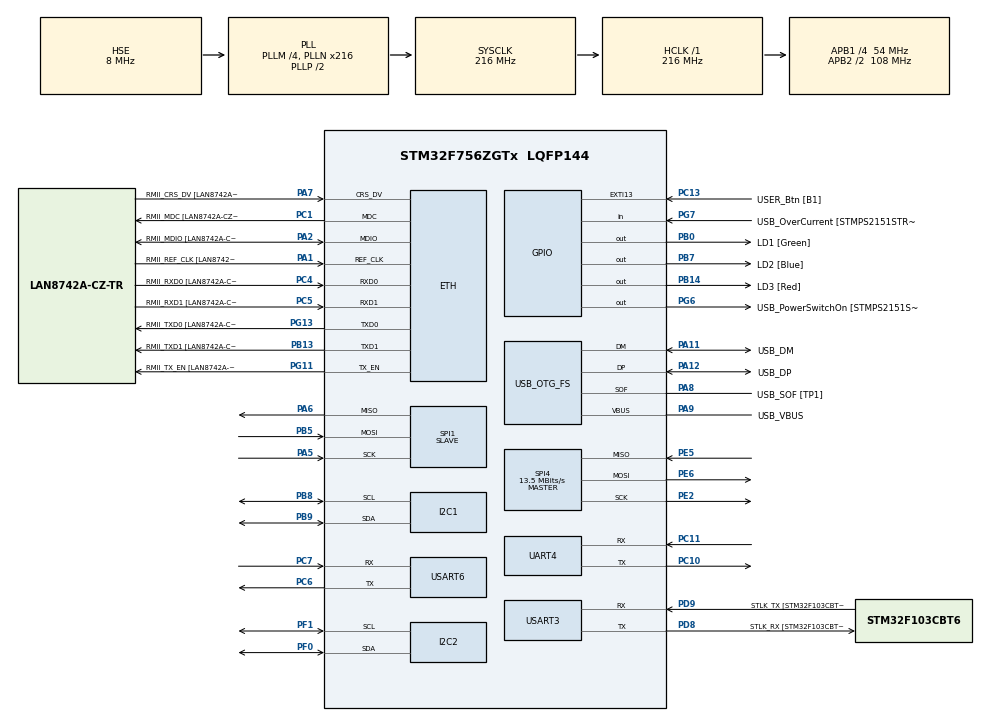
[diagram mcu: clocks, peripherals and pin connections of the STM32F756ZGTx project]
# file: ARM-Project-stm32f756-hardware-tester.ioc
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ADC1.Channel-0\#ChannelRegularConversion=ADC_CHANNEL_VREFINT
ADC1.NbrOfConversionFlag=1
ADC1.Rank-0\#ChannelRegularConversion=1
ADC1.SamplingTime-0\#ChannelRegularConversion=ADC_SAMPLETIME_480CYCLES
ADC1.master=1
CORTEX_M7.default_mode_Activation=1
Dma.ADC1.4.Direction=DMA_PERIPH_TO_MEMORY
Dma.ADC1.4.FIFOMode=DMA_FIFOMODE_DISABLE
Dma.ADC1.4.Instance=DMA2_Stream4
Dma.ADC1.4.MemDataAlignment=DMA_MDATAALIGN_HALFWORD
Dma.ADC1.4.MemInc=DMA_MINC_ENABLE
Dma.ADC1.4.Mode=DMA_NORMAL
Dma.ADC1.4.PeriphDataAlignment=DMA_PDATAALIGN_HALFWORD
Dma.ADC1.4.PeriphInc=DMA_PINC_DISABLE
Dma.ADC1.4.Priority=DMA_PRIORITY_LOW
Dma.I2C1_RX.7.Direction=DMA_PERIPH_TO_MEMORY
Dma.I2C1_RX.7.FIFOMode=DMA_FIFOMODE_DISABLE
Dma.I2C1_RX.7.Instance=DMA1_Stream0
Dma.I2C1_RX.7.MemDataAlignment=DMA_MDATAALIGN_BYTE
Dma.I2C1_RX.7.MemInc=DMA_MINC_ENABLE
Dma.I2C1_RX.7.Mode=DMA_NORMAL
Dma.I2C1_RX.7.PeriphDataAlignment=DMA_PDATAALIGN_BYTE
Dma.I2C1_RX.7.PeriphInc=DMA_PINC_DISABLE
Dma.I2C1_RX.7.Priority=DMA_PRIORITY_LOW
Dma.I2C1_TX.8.Direction=DMA_MEMORY_TO_PERIPH
Dma.I2C1_TX.8.FIFOMode=DMA_FIFOMODE_DISABLE
Dma.I2C1_TX.8.Instance=DMA1_Stream6
Dma.I2C1_TX.8.MemDataAlignment=DMA_MDATAALIGN_BYTE
Dma.I2C1_TX.8.MemInc=DMA_MINC_ENABLE
Dma.I2C1_TX.8.Mode=DMA_NORMAL
Dma.I2C1_TX.8.PeriphDataAlignment=DMA_PDATAALIGN_BYTE
Dma.I2C1_TX.8.PeriphInc=DMA_PINC_DISABLE
Dma.I2C1_TX.8.Priority=DMA_PRIORITY_LOW
Dma.I2C2_RX.5.Direction=DMA_PERIPH_TO_MEMORY
Dma.I2C2_RX.5.FIFOMode=DMA_FIFOMODE_DISABLE
Dma.I2C2_RX.5.Instance=DMA1_Stream3
Dma.I2C2_RX.5.MemDataAlignment=DMA_MDATAALIGN_BYTE
Dma.I2C2_RX.5.MemInc=DMA_MINC_ENABLE
Dma.I2C2_RX.5.Mode=DMA_NORMAL
Dma.I2C2_RX.5.PeriphDataAlignment=DMA_PDATAALIGN_BYTE
Dma.I2C2_RX.5.PeriphInc=DMA_PINC_DISABLE
Dma.I2C2_RX.5.Priority=DMA_PRIORITY_LOW
Dma.I2C2_TX.6.Direction=DMA_MEMORY_TO_PERIPH
Dma.I2C2_TX.6.FIFOMode=DMA_FIFOMODE_DISABLE
Dma.I2C2_TX.6.Instance=DMA1_Stream7
Dma.I2C2_TX.6.MemDataAlignment=DMA_MDATAALIGN_BYTE
Dma.I2C2_TX.6.MemInc=DMA_MINC_ENABLE
Dma.I2C2_TX.6.Mode=DMA_NORMAL
Dma.I2C2_TX.6.PeriphDataAlignment=DMA_PDATAALIGN_BYTE
Dma.I2C2_TX.6.PeriphInc=DMA_PINC_DISABLE
Dma.I2C2_TX.6.Priority=DMA_PRIORITY_LOW
Dma.Request0=SPI1_RX
Dma.Request1=SPI1_TX
Dma.Request10=UART4_TX
Dma.Request11=USART6_RX
Dma.Request12=USART6_TX
Dma.Request2=SPI4_RX
Dma.Request3=SPI4_TX
Dma.Request4=ADC1
Dma.Request5=I2C2_RX
Dma.Request6=I2C2_TX
Dma.Request7=I2C1_RX
Dma.Request8=I2C1_TX
Dma.Request9=UART4_RX
Dma.SPI1_RX.0.Direction=DMA_PERIPH_TO_MEMORY
Dma.SPI1_RX.0.FIFOMode=DMA_FIFOMODE_DISABLE
Dma.SPI1_RX.0.Instance=DMA2_Stream0
Dma.SPI1_RX.0.MemDataAlignment=DMA_MDATAALIGN_BYTE
Dma.SPI1_RX.0.MemInc=DMA_MINC_ENABLE
Dma.SPI1_RX.0.Mode=DMA_NORMAL
Dma.SPI1_RX.0.PeriphDataAlignment=DMA_PDATAALIGN_BYTE
Dma.SPI1_RX.0.PeriphInc=DMA_PINC_DISABLE
Dma.SPI1_RX.0.Priority=DMA_PRIORITY_LOW
Dma.SPI1_TX.1.Direction=DMA_MEMORY_TO_PERIPH
Dma.SPI1_TX.1.FIFOMode=DMA_FIFOMODE_DISABLE
Dma.SPI1_TX.1.Instance=DMA2_Stream5
Dma.SPI1_TX.1.MemDataAlignment=DMA_MDATAALIGN_BYTE
Dma.SPI1_TX.1.MemInc=DMA_MINC_ENABLE
Dma.SPI1_TX.1.Mode=DMA_NORMAL
Dma.SPI1_TX.1.PeriphDataAlignment=DMA_PDATAALIGN_BYTE
Dma.SPI1_TX.1.PeriphInc=DMA_PINC_DISABLE
Dma.SPI1_TX.1.Priority=DMA_PRIORITY_LOW
Dma.SPI4_RX.2.Direction=DMA_PERIPH_TO_MEMORY
Dma.SPI4_RX.2.FIFOMode=DMA_FIFOMODE_DISABLE
Dma.SPI4_RX.2.Instance=DMA2_Stream3
Dma.SPI4_RX.2.MemDataAlignment=DMA_MDATAALIGN_BYTE
Dma.SPI4_RX.2.MemInc=DMA_MINC_ENABLE
Dma.SPI4_RX.2.Mode=DMA_NORMAL
Dma.SPI4_RX.2.PeriphDataAlignment=DMA_PDATAALIGN_BYTE
Dma.SPI4_RX.2.PeriphInc=DMA_PINC_DISABLE
Dma.SPI4_RX.2.Priority=DMA_PRIORITY_LOW
Dma.SPI4_TX.3.Direction=DMA_MEMORY_TO_PERIPH
Dma.SPI4_TX.3.FIFOMode=DMA_FIFOMODE_DISABLE
Dma.SPI4_TX.3.Instance=DMA2_Stream1
Dma.SPI4_TX.3.MemDataAlignment=DMA_MDATAALIGN_BYTE
Dma.SPI4_TX.3.MemInc=DMA_MINC_ENABLE
Dma.SPI4_TX.3.Mode=DMA_NORMAL
Dma.SPI4_TX.3.PeriphDataAlignment=DMA_PDATAALIGN_BYTE
Dma.SPI4_TX.3.PeriphInc=DMA_PINC_DISABLE
Dma.SPI4_TX.3.Priority=DMA_PRIORITY_LOW
Dma.UART4_RX.9.Direction=DMA_PERIPH_TO_MEMORY
Dma.UART4_RX.9.FIFOMode=DMA_FIFOMODE_DISABLE
Dma.UART4_RX.9.Instance=DMA1_Stream2
Dma.UART4_RX.9.MemDataAlignment=DMA_MDATAALIGN_BYTE
Dma.UART4_RX.9.MemInc=DMA_MINC_ENABLE
Dma.UART4_RX.9.Mode=DMA_NORMAL
Dma.UART4_RX.9.PeriphDataAlignment=DMA_PDATAALIGN_BYTE
Dma.UART4_RX.9.PeriphInc=DMA_PINC_DISABLE
Dma.UART4_RX.9.Priority=DMA_PRIORITY_LOW
Dma.UART4_TX.10.Direction=DMA_MEMORY_TO_PERIPH
Dma.UART4_TX.10.FIFOMode=DMA_FIFOMODE_DISABLE
Dma.UART4_TX.10.Instance=DMA1_Stream4
Dma.UART4_TX.10.MemDataAlignment=DMA_MDATAALIGN_BYTE
Dma.UART4_TX.10.MemInc=DMA_MINC_ENABLE
Dma.UART4_TX.10.Mode=DMA_NORMAL
Dma.UART4_TX.10.PeriphDataAlignment=DMA_PDATAALIGN_BYTE
Dma.UART4_TX.10.PeriphInc=DMA_PINC_DISABLE
Dma.UART4_TX.10.Priority=DMA_PRIORITY_LOW
Dma.USART6_RX.11.Direction=DMA_PERIPH_TO_MEMORY
Dma.USART6_RX.11.FIFOMode=DMA_FIFOMODE_DISABLE
Dma.USART6_RX.11.Instance=DMA2_Stream2
Dma.USART6_RX.11.MemDataAlignment=DMA_MDATAALIGN_BYTE
Dma.USART6_RX.11.MemInc=DMA_MINC_ENABLE
Dma.USART6_RX.11.Mode=DMA_NORMAL
Dma.USART6_RX.11.PeriphDataAlignment=DMA_PDATAALIGN_BYTE
Dma.USART6_RX.11.PeriphInc=DMA_PINC_DISABLE
Dma.USART6_RX.11.Priority=DMA_PRIORITY_LOW
Dma.USART6_TX.12.Direction=DMA_MEMORY_TO_PERIPH
Dma.USART6_TX.12.FIFOMode=DMA_FIFOMODE_DISABLE
Dma.USART6_TX.12.Instance=DMA2_Stream6
Dma.USART6_TX.12.MemDataAlignment=DMA_MDATAALIGN_BYTE
Dma.USART6_TX.12.MemInc=DMA_MINC_ENABLE
Dma.USART6_TX.12.Mode=DMA_NORMAL
Dma.USART6_TX.12.PeriphDataAlignment=DMA_PDATAALIGN_BYTE
Dma.USART6_TX.12.PeriphInc=DMA_PINC_DISABLE
Dma.USART6_TX.12.Priority=DMA_PRIORITY_LOW
ETH.MediaInterface=HAL_ETH_RMII_MODE
ETH.PHY_Name=LAN8742A_PHY_ADDRESS
ETH.PHY_Value=0
ETH.PhyAddress=0
I2C1.OwnAddress=0x10
I2C1.Timing=0x20404768
I2C2.OwnAddress=0x20
I2C2.Timing=0x20404768
LWIP.BSP.number=1
LWIP.DHCP_DEBUG=LWIP_DBG_OFF
LWIP.ICMP_DEBUG=LWIP_DBG_ON
LWIP.IP_DEBUG=LWIP_DBG_ON
LWIP.RAW_DEBUG=LWIP_DBG_ON
LWIP.UDP_DEBUG=LWIP_DBG_ON
LWIP.Version=v2.1.2_Cube
LWIP0.BSP.STBoard=false
LWIP0.BSP.api=BSP_COMPONENT_DRIVER
LWIP0.BSP.component=LAN8742
LWIP0.BSP.instance=LAN8742
LWIP0.BSP.name=Driver_PHY
LWIP0.BSP.semaphore=S_LAN8742
LWIP0.BSP.solution=LAN8742
Mcu.Family=STM32F7
Mcu.Name=STM32F756ZGTx
Mcu.Package=LQFP144
NVIC.DMA1_Stream0_IRQn=true\:0\:0\:false\:false\:true\:false\:true\:true
NVIC.DMA1_Stream2_IRQn=true\:0\:0\:false\:false\:true\:false\:true\:true
NVIC.DMA1_Stream3_IRQn=true\:0\:0\:false\:false\:true\:false\:true\:true
NVIC.DMA1_Stream4_IRQn=true\:0\:0\:false\:false\:true\:false\:true\:true
NVIC.DMA1_Stream6_IRQn=true\:0\:0\:false\:false\:true\:false\:true\:true
NVIC.DMA1_Stream7_IRQn=true\:0\:0\:false\:false\:true\:false\:true\:true
NVIC.DMA2_Stream0_IRQn=true\:0\:0\:false\:false\:true\:false\:true\:true
NVIC.DMA2_Stream1_IRQn=true\:0\:0\:false\:false\:true\:false\:true\:true
NVIC.DMA2_Stream2_IRQn=true\:0\:0\:false\:false\:true\:false\:true\:true
NVIC.DMA2_Stream3_IRQn=true\:0\:0\:false\:false\:true\:false\:true\:true
NVIC.DMA2_Stream4_IRQn=true\:0\:0\:false\:false\:true\:false\:true\:true
NVIC.DMA2_Stream5_IRQn=true\:0\:0\:false\:false\:true\:false\:true\:true
NVIC.DMA2_Stream6_IRQn=true\:0\:0\:false\:false\:true\:false\:true\:true
NVIC.I2C1_ER_IRQn=true\:0\:0\:false\:false\:true\:true\:true\:true
NVIC.I2C1_EV_IRQn=true\:0\:0\:false\:false\:true\:true\:true\:true
NVIC.I2C2_ER_IRQn=true\:0\:0\:false\:false\:true\:true\:true\:true
NVIC.I2C2_EV_IRQn=true\:0\:0\:false\:false\:true\:true\:true\:true
NVIC.PriorityGroup=NVIC_PRIORITYGROUP_4
NVIC.TIM2_IRQn=true\:0\:0\:false\:false\:true\:true\:true\:true
NVIC.UART4_IRQn=true\:0\:0\:false\:false\:true\:true\:true\:true
NVIC.USART6_IRQn=true\:0\:0\:false\:false\:true\:true\:true\:true
PA1.GPIO_Label=RMII_REF_CLK [LAN8742A-CZ-TR_REFCLK0]
PA1.Mode=RMII
PA1.Signal=ETH_REF_CLK
PA10.GPIO_Label=USB_ID
PA10.Signal=USB_OTG_FS_ID
PA11.GPIO_Label=USB_DM
PA11.Mode=Device_Only
PA11.Signal=USB_OTG_FS_DM
PA12.GPIO_Label=USB_DP
PA12.Mode=Device_Only
PA12.Signal=USB_OTG_FS_DP
PA13.GPIO_Label=TMS
PA13.Mode=Serial_Wire
PA13.Signal=SYS_JTMS-SWDIO
PA14.GPIO_Label=TCK
PA14.Mode=Serial_Wire
PA14.Signal=SYS_JTCK-SWCLK
PA2.GPIO_Label=RMII_MDIO [LAN8742A-CZ-TR_MDIO]
PA2.Mode=RMII
PA2.Signal=ETH_MDIO
PA5.Mode=Full_Duplex_Slave
PA5.Signal=SPI1_SCK
PA6.Mode=Full_Duplex_Slave
PA6.Signal=SPI1_MISO
PA7.GPIO_Label=RMII_CRS_DV [LAN8742A-CZ-TR_CRS_DV]
PA7.Mode=RMII
PA7.Signal=ETH_CRS_DV
PA8.GPIO_Label=USB_SOF [TP1]
PA8.Mode=Activate_SOF_FS
PA8.Signal=USB_OTG_FS_SOF
PA9.GPIO_Label=USB_VBUS
PA9.Mode=Activate_VBUS
PA9.Signal=USB_OTG_FS_VBUS
PB0.GPIO_Label=LD1 [Green]
PB0.Signal=GPIO_Output
PB13.GPIO_Label=RMII_TXD1 [LAN8742A-CZ-TR_TXD1]
PB13.Mode=RMII
PB13.Signal=ETH_TXD1
PB14.GPIO_Label=LD3 [Red]
PB14.Signal=GPIO_Output
PB3.GPIO_Label=SW0
PB3.Signal=SYS_JTDO-SWO
PB5.Mode=Full_Duplex_Slave
PB5.Signal=SPI1_MOSI
PB7.GPIO_Label=LD2 [Blue]
PB7.Signal=GPIO_Output
PB8.GPIO_Pu=GPIO_PULLUP
PB8.Mode=I2C
PB8.Signal=I2C1_SCL
PB9.GPIO_Pu=GPIO_PULLUP
PB9.Mode=I2C
PB9.Signal=I2C1_SDA
PC1.GPIO_Label=RMII_MDC [LAN8742A-CZ-TR_MDC]
PC1.Mode=RMII
PC1.Signal=ETH_MDC
PC10.Mode=Asynchronous
PC10.Signal=UART4_TX
PC11.Mode=Asynchronous
PC11.Signal=UART4_RX
PC13.GPIO_Label=USER_Btn [B1]
PC13.Signal=GPXTI13
PC14/OSC32_IN.Mode=LSE-External-Oscillator
PC14/OSC32_IN.Signal=RCC_OSC32_IN
PC15/OSC32_OUT.Mode=LSE-External-Oscillator
PC15/OSC32_OUT.Signal=RCC_OSC32_OUT
PC4.GPIO_Label=RMII_RXD0 [LAN8742A-CZ-TR_RXD0]
PC4.Mode=RMII
PC4.Signal=ETH_RXD0
PC5.GPIO_Label=RMII_RXD1 [LAN8742A-CZ-TR_RXD1]
PC5.Mode=RMII
PC5.Signal=ETH_RXD1
PC6.Mode=Asynchronous
PC6.Signal=USART6_TX
PC7.Mode=Asynchronous
PC7.Signal=USART6_RX
PD8.GPIO_Label=STLK_RX [STM32F103CBT6_PA3]
PD8.Mode=Asynchronous
PD8.Signal=USART3_TX
PD9.GPIO_Label=STLK_TX [STM32F103CBT6_PA2]
PD9.Mode=Asynchronous
PD9.Signal=USART3_RX
PE2.Mode=Full_Duplex_Master
PE2.Signal=SPI4_SCK
PE5.Mode=Full_Duplex_Master
PE5.Signal=SPI4_MISO
PE6.Mode=Full_Duplex_Master
PE6.Signal=SPI4_MOSI
PF0.GPIO_Pu=GPIO_PULLUP
PF0.Mode=I2C
PF0.Signal=I2C2_SDA
PF1.GPIO_Pu=GPIO_PULLUP
PF1.Mode=I2C
PF1.Signal=I2C2_SCL
PG11.GPIO_Label=RMII_TX_EN [LAN8742A-CZ-TR_TXEN]
PG11.Mode=RMII
PG11.Signal=ETH_TX_EN
PG13.GPIO_Label=RMII_TXD0 [LAN8742A-CZ-TR_TXD0]
PG13.Mode=RMII
PG13.Signal=ETH_TXD0
PG6.GPIO_Label=USB_PowerSwitchOn [STMPS2151STR_EN]
PG6.Signal=GPIO_Output
PG7.GPIO_Label=USB_OverCurrent [STMPS2151STR_FAULT]
PG7.Signal=GPIO_Input
PH0/OSC_IN.GPIO_Label=MCO [STM32F103CBT6_PA8]
PH0/OSC_IN.Mode=HSE-External-Clock-Source
PH0/OSC_IN.Signal=RCC_OSC_IN
PH1/OSC_OUT.Mode=HSE-External-Clock-Source
PH1/OSC_OUT.Signal=RCC_OSC_OUT
ProjectManager.HeapSize=0x200
ProjectManager.StackSize=0x400
ProjectManager.TargetToolchain=STM32CubeIDE
RCC.48MHZClocksFreq_Value=24000000
RCC.AHBFreq_Value=216000000
RCC.APB1CLKDivider=RCC_HCLK_DIV4
RCC.APB1Freq_Value=54000000
RCC.APB1TimFreq_Value=108000000
RCC.APB2CLKDivider=RCC_HCLK_DIV2
RCC.APB2Freq_Value=108000000
RCC.APB2TimFreq_Value=216000000
RCC.CortexFreq_Value=216000000
RCC.HCLKFreq_Value=216000000
RCC.HSE_VALUE=8000000
RCC.HSI_VALUE=16000000
RCC.PLLM=4
RCC.PLLMUL=RCC_PLL_MUL9
RCC.PLLN=216
RCC.PLLQ=9
RCC.PRESCALERUSB=RCC_USBCLKSOURCE_PLL_DIV1_5
RCC.SYSCLKFreq_VALUE=216000000
RCC.SYSCLKSource=RCC_SYSCLKSOURCE_PLLCLK
RCC.SYSCLKSourceVirtual=RCC_SYSCLKSOURCE_PLLCLK
RCC.USBFreq_Value=48000000
RCC.VCOOutputFreq_Value=432000000
SPI1.CLKPhase=SPI_PHASE_2EDGE
SPI1.CLKPolarity=SPI_POLARITY_HIGH
SPI1.DataSize=SPI_DATASIZE_8BIT
SPI1.Direction=SPI_DIRECTION_2LINES
SPI1.Mode=SPI_MODE_SLAVE
SPI1.VirtualType=VM_SLAVE
SPI4.BaudRatePrescaler=SPI_BAUDRATEPRESCALER_8
SPI4.CLKPhase=SPI_PHASE_2EDGE
SPI4.CLKPolarity=SPI_POLARITY_HIGH
SPI4.CalculateBaudRate=13.5 MBits/s
SPI4.DataSize=SPI_DATASIZE_8BIT
SPI4.Direction=SPI_DIRECTION_2LINES
SPI4.Mode=SPI_MODE_MASTER
SPI4.VirtualType=VM_MASTER
TIM2.Period=0xffffffff
TIM2.Prescaler=107
USART3.VirtualMode-Asynchronous=VM_ASYNC
USART6.VirtualMode-Asynchronous=VM_ASYNC
USB_OTG_FS.VirtualMode=Device_Only
VP_ADC1_Vref_Input.Mode=IN-Vrefint
VP_CRC_VS_CRC.Mode=CRC_Activate
VP_LWIP_VS_Enabled.Mode=Enabled
VP_TIM2_VS_ClockSourceINT.Mode=Internal
board=NUCLEO-F756ZG

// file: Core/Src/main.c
/* USER CODE BEGIN Header */
/**
  ******************************************************************************
  * @file           : main.c
  * @brief          : Main program body
  ******************************************************************************
  * @attention
  *
  * Copyright (c) 2026 STMicroelectronics.
  * All rights reserved.
  *
  * This software is licensed under terms that can be found in the LICENSE file
  * in the root directory of this software component.
  * If no LICENSE file comes with this software, it is provided AS-IS.
  *
  ******************************************************************************
  */
/* USER CODE END Header */
#include "main.h"
#include "adc.h"
#include "crc.h"
#include "dma.h"
#include "i2c.h"
#include "lwip.h"
#include "spi.h"
#include "tim.h"
#include "usart.h"
#include "usb_otg.h"
#include "gpio.h"

/* USER CODE BEGIN Includes */
#include "user.h"
/* USER CODE END Includes */

void SystemClock_Config(void);
static void MPU_Config(void);

int main(void)
{

  /* MPU Configuration--------------------------------------------------------*/
  MPU_Config();

  /* MCU Configuration--------------------------------------------------------*/

  /* Reset of all peripherals, Initializes the Flash interface and the Systick. */
  HAL_Init();

  /* Configure the system clock */
  SystemClock_Config();

  /* Initialize all configured peripherals */
  MX_GPIO_Init();
  MX_DMA_Init();
  MX_USART3_UART_Init();
  MX_USB_OTG_FS_PCD_Init();
  MX_SPI1_Init();
  MX_SPI4_Init();
  MX_ADC1_Init();
  MX_TIM2_Init();
  MX_I2C1_Init();
  MX_I2C2_Init();
  MX_UART4_Init();
  MX_USART6_UART_Init();
  MX_CRC_Init();
  MX_LWIP_Init();
  /* USER CODE BEGIN 2 */
  user_main();
  /* USER CODE END 2 */

  /* Infinite loop */
  while (1)
  {
	  MX_LWIP_Process();
	  user_loop();
  }
}

void SystemClock_Config(void)
{
  RCC_OscInitTypeDef RCC_OscInitStruct = {0};
  RCC_ClkInitTypeDef RCC_ClkInitStruct = {0};

  /** Configure LSE Drive Capability
  */
  HAL_PWR_EnableBkUpAccess();

  /** Configure the main internal regulator output voltage
  */
  __HAL_RCC_PWR_CLK_ENABLE();
  __HAL_PWR_VOLTAGESCALING_CONFIG(PWR_REGULATOR_VOLTAGE_SCALE1);

  /** Initializes the RCC Oscillators according to the specified parameters
  * in the RCC_OscInitTypeDef structure.
  */
  RCC_OscInitStruct.OscillatorType = RCC_OSCILLATORTYPE_HSE;
  RCC_OscInitStruct.HSEState = RCC_HSE_BYPASS;
  RCC_OscInitStruct.PLL.PLLState = RCC_PLL_ON;
  RCC_OscInitStruct.PLL.PLLSource = RCC_PLLSOURCE_HSE;
  RCC_OscInitStruct.PLL.PLLM = 4;
  RCC_OscInitStruct.PLL.PLLN = 216;
  RCC_OscInitStruct.PLL.PLLP = RCC_PLLP_DIV2;
  RCC_OscInitStruct.PLL.PLLQ = 9;
  if (HAL_RCC_OscConfig(&RCC_OscInitStruct) != HAL_OK)
  {
    Error_Handler();
  }

  /** Activate the Over-Drive mode
  */
  if (HAL_PWREx_EnableOverDrive() != HAL_OK)
  {
    Error_Handler();
  }

  /** Initializes the CPU, AHB and APB buses clocks
  */
  RCC_ClkInitStruct.ClockType = RCC_CLOCKTYPE_HCLK|RCC_CLOCKTYPE_SYSCLK
                              |RCC_CLOCKTYPE_PCLK1|RCC_CLOCKTYPE_PCLK2;
  RCC_ClkInitStruct.SYSCLKSource = RCC_SYSCLKSOURCE_PLLCLK;
  RCC_ClkInitStruct.AHBCLKDivider = RCC_SYSCLK_DIV1;
  RCC_ClkInitStruct.APB1CLKDivider = RCC_HCLK_DIV4;
  RCC_ClkInitStruct.APB2CLKDivider = RCC_HCLK_DIV2;

  if (HAL_RCC_ClockConfig(&RCC_ClkInitStruct, FLASH_LATENCY_7) != HAL_OK)
  {
    Error_Handler();
  }
}

 /* MPU Configuration */

void MPU_Config(void)
{
  MPU_Region_InitTypeDef MPU_InitStruct = {0};

  /* Disables the MPU */
  HAL_MPU_Disable();

  /** Initializes and configures the Region and the memory to be protected
  */
  MPU_InitStruct.Enable = MPU_REGION_ENABLE;
  MPU_InitStruct.Number = MPU_REGION_NUMBER0;
  MPU_InitStruct.BaseAddress = 0x0;
  MPU_InitStruct.Size = MPU_REGION_SIZE_4GB;
  MPU_InitStruct.SubRegionDisable = 0x87;
  MPU_InitStruct.TypeExtField = MPU_TEX_LEVEL0;
  MPU_InitStruct.AccessPermission = MPU_REGION_NO_ACCESS;
  MPU_InitStruct.DisableExec = MPU_INSTRUCTION_ACCESS_DISABLE;
  MPU_InitStruct.IsShareable = MPU_ACCESS_SHAREABLE;
  MPU_InitStruct.IsCacheable = MPU_ACCESS_NOT_CACHEABLE;
  MPU_InitStruct.IsBufferable = MPU_ACCESS_NOT_BUFFERABLE;

  HAL_MPU_ConfigRegion(&MPU_InitStruct);
  /* Enables the MPU */
  HAL_MPU_Enable(MPU_PRIVILEGED_DEFAULT);

}

void Error_Handler(void)
{
  __disable_irq();
  while (1)
  {
  }
}
